# CEC1702 register map
Vendor: Microchip Technology; Series: CEC1702Q; File version: 0
CPU: CM4 r1p0, little endian, MPU, FPU, 3 interrupt priority bits, 155 interrupts
Registers are 32-bit, read-write, reset 0x0 unless marked. A register's access mark holds for its fields unless they carry their own. Offsets are from the block's base; [hi:lo] are bit positions.

## CNT_TMR0 — This interface is a 16-bit auto-reloading timer/counter.
Base 0x40000D00; register names take the prefix CNT_TMR_
Same registers: CNT_TMR1 0x40000D20, CNT_TMR2 0x40000D40, CNT_TMR3 0x40000D60
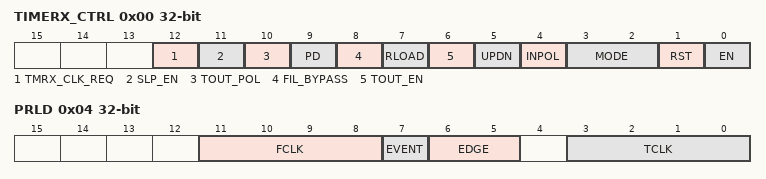
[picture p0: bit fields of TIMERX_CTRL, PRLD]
0x00 TIMERX_CTRL — This bit reflects the current state of the timer's Clock_Required output signal.
  [12] TMRX_CLK_REQ — This bit reflects the current state of the timer's Clock_Required output signal. 1=The main clock is required by this block; 0=The main clock is not required by this block.
  [11] SLP_EN — This bit reflects the current state of the timer's Sleep_Enable input signal. 1=Normal operation; 0=Sleep Mode is requested.
  [10] TOUT_POL — This bit determines the polarity of the TOUTx output signal. In timer modes that toggle the TOUTx signal, this polarity bit will not have a perceivable difference, except to determine the inactive state. In One-Shot mode this determines if the pulsed output is active high or active low. 1=Active low; 0=Active high.
  [9] PD — Power Down. 1=The timer is powered down and all clocks are gated; 0=The timer is in a running state.
  [8] FIL_BYPASS — This bit is used to enable or disable the noise filter on the TINx input signal. 1=Bypass Mode: input filter disabled. The TINx input directly affects the timer; 0=Filter Mode: input filter enabled. The TINx input is filtered by the input filter.
  [7] RLOAD — Reload Control. This bit controls how the timer is reloaded on overflow or underflow in Event and Timer modes. It has no effect in One shot mode. 1=Reload timer from Timer Reload Register and continue counting; 0=Roll timer over to FFFFh and continue counting when counting down and rolls over to 0000h and continues counting when counting up.
  [6] TOUT_EN — This bit enables the TOUTx pin. 1=TOUTx pin function is enabled; 0=TOUTx pin is inactive.
  [5] UPDN — In Event Mode, this bit selects the timer count direction. In Timer Mode enables timer control by the TINx input pin. Event Mode: 1=The timer counts up; 0=The timer counts down. Timer Mode:; 1=TINx pin pauses the timer when de-asserted; 0=TINx pin has no effect on the timer.
  [4] INPOL — This bit selects the polarity of the TINx input. 1=TINx is active low; 0=TINx is active high.
  [3:2] MODE — Timer Mode. 3=Measurement Mode; 2=One Shot Mode; 1=Event Mode; 0=Timer Mode.
    0=TIMER_MODE (0=Timer Mode); 1=EVENT_MODE (1=Event Mode); 2=ONE_SHOT_MODE (2=One Shot Mode); 3=MEASUREMENT_MODE (3=Measurement Mode)
  [1] RST — This bit stops the timer and resets the internal counter to the value in the Timer Reload Register. This bit also clears the ENABLE bit if it is set. This bit is self-clearing after the timer is reset. Firmware must poll the. RESET bit in order to determine when the timer is active after reset. Interrupts are blocked only when RESET takes effect and the ENABLE bit is cleared. If interrupts are not desired, firmware must mask the interrupt in the interrupt block. 1=Timer reset; 0=Normal timer operation.
  [0] EN — This bit is used to start and stop the timer. This bit does not reset the timer count but does reset the timer pulse output. This bit will be cleared when the timer stops counting in One-Shot mode. The ENABLE bit is cleared after a. RESET cycle has completed. Firmware must poll the RESET bit in order to determine when the timer is active after reset. 1=Timer is enabled; 0=Timer is disabled.
0x04 PRLD — This is the value of the Timer pre-load for the counter. This is used by H/W when the counter is to be restarted automatically; this will become the new value of the counter upon restart.
  [11:8] FCLK — Timer Clock Select. This field determines the clock source for the TINx noise filter. The available frequencies are the same as for TCLK.
  [7] EVENT — Event Select. This bit is used to select the count source when the timer is operating in Event Mode. 1=TINx is count source; 0=Timer x-1 overflow is count source.
  [6:5] EDGE — This field selects which edge of the TINx input signal affects the timer in Event Mode, One-Shot Mode and Measurement Mode. Event Mode: 11b=No event selected; 10b=Counts rising and falling edges; 01b=Counts rising edges; 00b=Counts falling edges. One-Shot Mode: 11b=Start counting when the Enable bit is set; 10b=Starts counting on a rising or falling edge; 01b=Starts counting on a rising edge; 00b=Starts counting on a falling edge. Measurement Mode: 11b=No event selected; 10b=Measures the time between rising edges and falling edges and the time between falling edges and rising edges; 01b=Measures the time between rising edges; 00b=Measures the time between falling edges.
  [3:0] TCLK — Timer Clock Select. This field determines the clock source for the 16-bit counter in the timer.
0x08 TIMERX_RLD reset 0xFFFF — This register is used in Timer and One-Shot modes to set the lower limit of the timer.
  [15:0] TMR_RLD — The Timer Reload register is used in Timer and One-Shot modes to set the lower limit of the timer. In Event mode the Timer Reload register sets either the upper or lower limit of the timer depending on if the timer is counting up or down. Valid Timer Reload values are 0001h - FFFFh. If the timer is running, the reload value will not be updated until the timer overflows or underflows. Programming a 0000h as a preload value is not a valid count value. Using a value of 0000h will cause unpredictable behavior.
0x0C TIMERX_CNT reset 0xFFFF — This register returns the current value of the timer in all modes.
  [15:0] TMR_CNT — This is the current value of the timer in all modes.

## Notices in the file
Copyright (c) 2023 Microchip Technology Inc.
SPDX-License-Identifier: Apache-2.0
Licensed under the Apache License, Version 2.0 (the "License");
you may not use this file except in compliance with the License.
You may obtain a copy of the License at
http://www.apache.org/licenses/LICENSE-2.0
Unless required by applicable law or agreed to in writing, software
distributed under the License is distributed on an "AS IS" BASIS,
WITHOUT WARRANTIES OR CONDITIONS OF ANY KIND, either express or implied.
See the License for the specific language governing permissions and
limitations under the License.
